VERSION ""

NS_ :

BS_:

BU_: XXX

BO_ 2034 NEW_MSG_1: 8 XXX

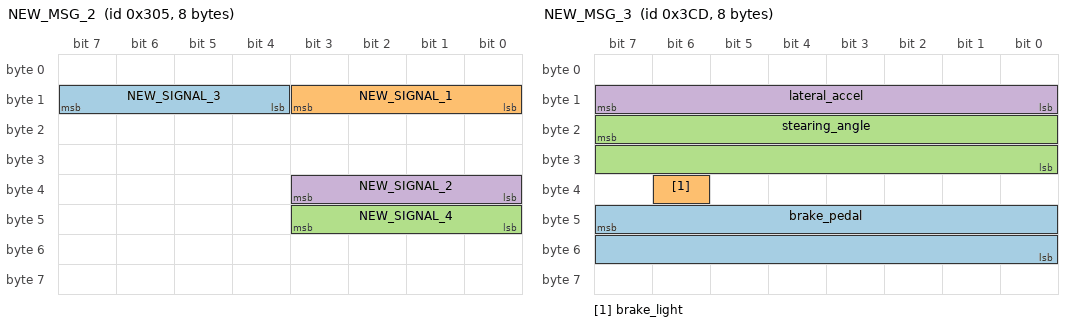
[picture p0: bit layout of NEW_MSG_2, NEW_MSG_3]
BO_ 773 NEW_MSG_2: 8 XXX
 SG_ NEW_SIGNAL_3 : 15|4@0+ (1,0) [0|15] "" XXX
 SG_ NEW_SIGNAL_1 : 8|4@1+ (1,0) [0|7] "" XXX
 SG_ NEW_SIGNAL_4 : 40|4@1+ (1,0) [0|15] "" XXX
 SG_ NEW_SIGNAL_2 : 32|4@1+ (1,0) [0|3] "" XXX

BO_ 973 NEW_MSG_3: 8 XXX
 SG_ brake_pedal : 47|16@0- (1,0) [0|255] "" XXX
 SG_ brake_light : 38|1@0+ (1,0) [0|3] "" XXX
 SG_ stearing_angle : 23|16@0- (1,0) [0|65535] "" XXX
 SG_ lateral_accel : 15|8@0- (1,0) [0|65535] "" XXX

BO_ 520 NEW_MSG_4: 8 XXX
 SG_ NEW_SIGNAL_2 : 7|16@0+ (1,0) [0|8388607] "" XXX
 SG_ NEW_SIGNAL_1 : 23|16@0+ (1,0) [0|65535] "" XXX

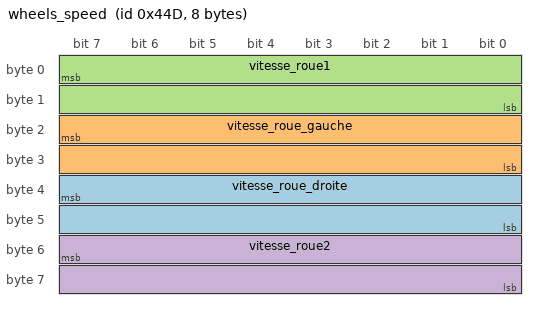
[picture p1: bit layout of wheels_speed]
BO_ 1101 wheels_speed: 8 XXX
 SG_ vitesse_roue_droite : 39|16@0+ (1,0) [0|65535] "" XXX
 SG_ vitesse_roue_gauche : 23|16@0+ (1,0) [0|65535] "" XXX
 SG_ vitesse_roue1 : 7|16@0+ (1,0) [0|65535] "" XXX
 SG_ vitesse_roue2 : 55|16@0+ (1,0) [0|65535] "" XXX
